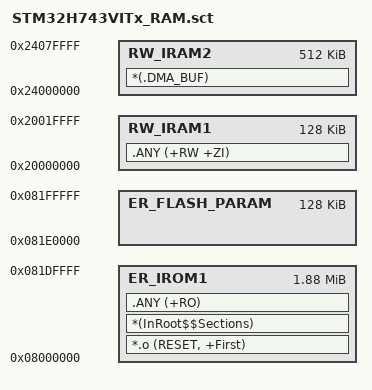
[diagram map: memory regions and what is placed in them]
; *************************************************************
; *** STM32H743VI scatter file: 代码在 Flash，数据在 DTCM，DMA 缓冲在 AXI SRAM ***
; *** DMA1/DMA2 无法访问 DTCM(0x20000000)，必须将 DMA 缓冲放在 AXI SRAM(0x24000000) ***
; *** 参数区与 Driver/Flash/Flash_Param.h 一致：FLASH_PARAM_BASE_ADDR ~ END_ADDR ***
; *** 0x081E0000-0x081FFFFF 保留，勿将 RO/代码放入（整扇区由 Flash_Param 擦写） ***
; *************************************************************

LR_IROM1 0x08000000 0x00200000 {
  ; 应用 RO：止于参数区之前（0x081E0000 - 0x08000000 = 0x001E0000）
  ER_IROM1 0x08000000 0x001E0000 {
    *.o (RESET, +First)
    *(InRoot$$Sections)
    .ANY (+RO)
  }
  ; 与 FLASH_PARAM_BASE_ADDR(0x081E0000)、FLASH_PARAM_END_ADDR(0x081FFFFF) 对齐的保留区
  ER_FLASH_PARAM 0x081E0000 0x00020000 {
  }
  ; DTCM: 128KB，用于 stack/heap/默认数据（DMA 不可访问）
  RW_IRAM1 0x20000000 0x00020000 {
    .ANY (+RW +ZI)
  }
  ; AXI SRAM: 512KB，DMA 可访问，仅放 UART DMA TX 缓冲
  RW_IRAM2 0x24000000 0x00080000 {
    *(.DMA_BUF)
  }
}
